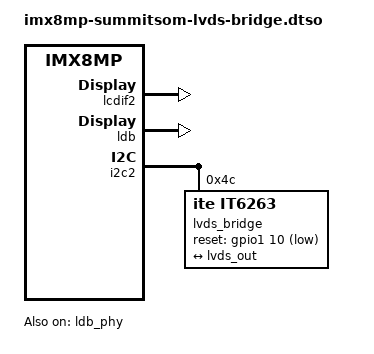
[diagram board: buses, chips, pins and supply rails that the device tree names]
// SPDX-License-Identifier: LicenseRef-Ezurio-Clause
/*
 * Copyright 2021 Ezurio
 */

/dts-v1/;
/plugin/;

#include <dt-bindings/gpio/gpio.h>

&lcdif2 {
	status = "okay";
};

&ldb {
	status = "okay";

	#address-cells = <1>;
	#size-cells = <0>;

	lvds-channel@0 {
		status = "okay";

		#address-cells = <1>;
		#size-cells = <0>;

		port@1 {
			reg = <1>;

			lvds_out: endpoint {
				remote-endpoint = <&it6263_in>;
			};
		};
	};
};

&ldb_phy {
	status = "okay";
};

&i2c2 {
	#address-cells = <1>;
	#size-cells = <0>;

	lvds_bridge: lvds-to-hdmi-bridge@4c {
		compatible = "ite,it6263";
		reg = <0x4c>;
		reset-gpios = <&gpio1 10 GPIO_ACTIVE_LOW>;

		port {
			it6263_in: endpoint {
				remote-endpoint = <&lvds_out>;
			};
		};
	};
};

#include "imx8mp-summitsom-gpu.dtsi"
